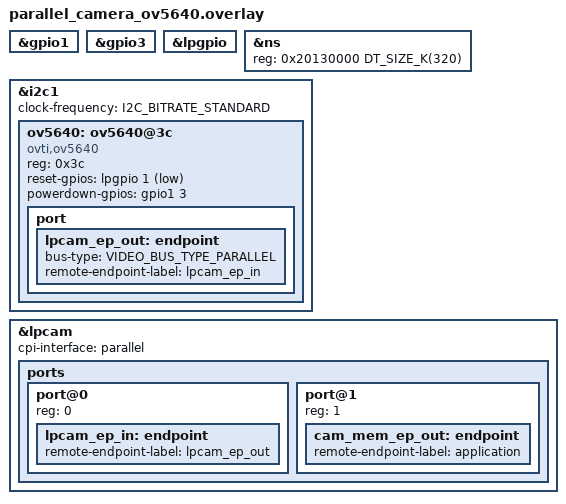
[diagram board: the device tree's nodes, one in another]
/* Copyright (C) Alif Semiconductor - All Rights Reserved.
 * Use, distribution and modification of this code is permitted under the
 * terms stated in the Alif Semiconductor Software License Agreement
 *
 * You should have received a copy of the Alif Semiconductor Software
 * License Agreement with this file. If not, please write to:
 * contact@alifsemi.com, or visit: https: //alifsemi.com/license
 *
 */

/*
 * OV5640 parallel (DVP) camera on the Alif E1C StarterKit board.
 *
 * The sensor is wired to the Low-Power Camera Parallel Interface (LP-CPI /
 * lpcam) through the Cypress interconnect board:
 *   - SCCB control  : I2C1 (P2_6 SDA_B, P2_7 SCL_B)
 *   - Parallel data : LPCAM_D0..D7, VSYNC, HSYNC, PCLK, XVCLK (pinctrl_lpcam)
 *
 * The XVCLK is generated by the board internal oscillator (solder the
 * XCLK/Int jumper); external XVCLK is not supported in this configuration.
 *
 * The lpcam node advertises "alif,cam", so the application picks it up via
 * DEVICE_DT_GET_ONE(alif_cam).
 */

#include <dt-bindings/pinctrl/balletto-pinctrl.h>
#include <dt-bindings/i2c/i2c.h>
#include <dt-bindings/gpio/gpio.h>
#include <dt-bindings/video/video-interfaces.h>

&gpio1 {
	status = "okay";
};

/*
 * GPIO port 3 pin 2 controls the on-board level translator/buffer between the
 * SoC LP-CPI pins and the OV5640 module on the E1C StarterKit. It must be
 * driven active to enable the camera signal path (clock/data and SCCB).
 */
&gpio3 {
	status = "okay";
};

&lpgpio {
	status = "okay";
};

/*
 * The LP-CPI (lpcam) DMA master can only write to memory the TGU marks as
 * non-secure. Enabling &ns makes the SoC linker relocate the video buffer
 * pool (kheap_buf_video_buffer_pool) into the NON_SECURE0 window and
 * TGU_Setup() marks that DTCM block non-secure.
 *
 * The default NON_SECURE0 window (0x20020000, 512K) sits in the middle of
 * DTCM and collides with this app's large secure buffers (TFLM tensor arena,
 * image_data, rgb565_crop) which the linker allocates bottom-up from
 * 0x20000000. Relocate the window to the top 320K of the 1.5MB DTCM (enough
 * for the two 160K video buffer pool slots) so the secure buffers get the
 * low ~1.19MB and never overlap the non-secure video pool.
 */
&ns {
	reg = <0x20130000 DT_SIZE_K(320)>;
	status = "okay";
};

&i2c1 {
	status = "okay";
	clock-frequency = <I2C_BITRATE_STANDARD>;

	ov5640: ov5640@3c {
		compatible = "ovti,ov5640";
		reg = <0x3c>;
		status = "okay";

		reset-gpios = <&lpgpio 1 GPIO_ACTIVE_LOW>;
		powerdown-gpios = <&gpio1 3 GPIO_ACTIVE_HIGH>;

		port {
			lpcam_ep_out: endpoint {
				bus-type = <VIDEO_BUS_TYPE_PARALLEL>;
				remote-endpoint-label = "lpcam_ep_in";
			};
		};
	};
};

&lpcam {
	status = "okay";
	cpi-interface = "parallel";

	ports {
		#address-cells = <1>;
		#size-cells = <0>;

		/* Camera input endpoint. For LP-CAM it is only the camera. */
		port@0 {
			reg = <0>;
			lpcam_ep_in: endpoint {
				remote-endpoint-label = "lpcam_ep_out";
			};
		};

		/* Video buffer output endpoint (memory). */
		port@1 {
			reg = <1>;
			cam_mem_ep_out: endpoint {
				remote-endpoint-label = "application";
			};
		};
	};
};
